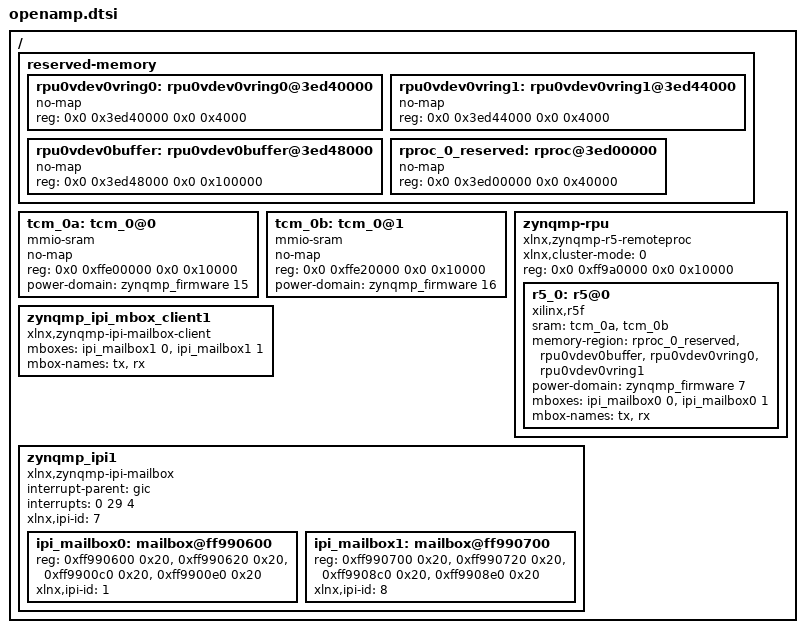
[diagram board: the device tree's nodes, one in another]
/ {
	reserved-memory {
		#address-cells = <2>;
		#size-cells = <2>;
		ranges;

		rpu0vdev0vring0: rpu0vdev0vring0@3ed40000 {
			no-map;
			reg = <0x0 0x3ed40000 0x0 0x4000>;
		};

		rpu0vdev0vring1: rpu0vdev0vring1@3ed44000 {
			no-map;
			reg = <0x0 0x3ed44000 0x0 0x4000>;
		};

		rpu0vdev0buffer: rpu0vdev0buffer@3ed48000 {
			no-map;
			reg = <0x0 0x3ed48000 0x0 0x100000>;
		};

		rproc_0_reserved: rproc@3ed00000 {
			no-map;
			reg = <0x0 0x3ed00000 0x0 0x40000>;
		};
	};
	
	tcm_0a: tcm_0@0 {
		no-map;
		reg = <0x0 0xffe00000 0x0 0x10000>;
		compatible = "mmio-sram";
		power-domain = <&zynqmp_firmware 15>;
	};

	tcm_0b: tcm_0@1 {
		no-map;
		reg = <0x0 0xffe20000 0x0 0x10000>;
		compatible = "mmio-sram";
		power-domain = <&zynqmp_firmware 16>;
	};

	zynqmp-rpu {
		compatible = "xlnx,zynqmp-r5-remoteproc";
		xlnx,cluster-mode = <0>; /* lockstep (0), split (1) */
		reg = <0x0 0xff9a0000 0x0 0x10000>;
		ranges;
		#address-cells = <2>;
		#size-cells = <2>;

		r5_0: r5@0 {
			compatible = "xilinx,r5f";
			#address-cells = <2>;
			#size-cells = <2>;
			ranges;
			sram = <&tcm_0a>, <&tcm_0b>;
			memory-region = <&rproc_0_reserved>, <&rpu0vdev0buffer>, <&rpu0vdev0vring0>, <&rpu0vdev0vring1>;
			power-domain = <&zynqmp_firmware 7>;
			mboxes = <&ipi_mailbox0 0>, <&ipi_mailbox0 1>;
			mbox-names = "tx", "rx";
		};
	};

	zynqmp_ipi_mbox_client1 {
		compatible = "xlnx,zynqmp-ipi-mailbox-client";
		mboxes = <&ipi_mailbox1 0 &ipi_mailbox1 1>;
		mbox-names = "tx", "rx";
	};

	zynqmp_ipi1 {
		compatible = "xlnx,zynqmp-ipi-mailbox";
		interrupt-parent = <&gic>;
		interrupts = <0 29 4>;
		xlnx,ipi-id = <7>; /* Channel 7 (PL0) */
		#address-cells = <1>;
		#size-cells = <1>;
		ranges;

		/* APU (PL0) <-> RPU0 (RPU0) IPI mailbox controller (openamp) */
		ipi_mailbox0: mailbox@ff990600 {
			reg = <0xff990600 0x20>, /* Channel 7 request buffer */
			      <0xff990620 0x20>,
			      <0xff9900c0 0x20>, /* Channel 1 request buffer */
			      <0xff9900e0 0x20>;
			reg-names = "local_request_region",
				    "local_response_region",
				    "remote_request_region",
				    "remote_response_region";
			#mbox-cells = <1>;
			xlnx,ipi-id = <1>; /* Channel 1 (RPU0) */
		};

		/* APU (PL0) <-> RPU0 (PL1) IPI mailbox controller (mailbox) */
		ipi_mailbox1: mailbox@ff990700 {
			reg = <0xff990700 0x20>, /* Channel 7 request buffer */
			      <0xff990720 0x20>,
			      <0xff9908c0 0x20>, /* Channel 8 request buffer */
			      <0xff9908e0 0x20>;
			reg-names = "local_request_region",
				    "local_response_region",
				    "remote_request_region",
				    "remote_response_region";
			#mbox-cells = <1>;
			xlnx,ipi-id = <8>; /* Channel 8 (PL1) */
		};
	};
};
